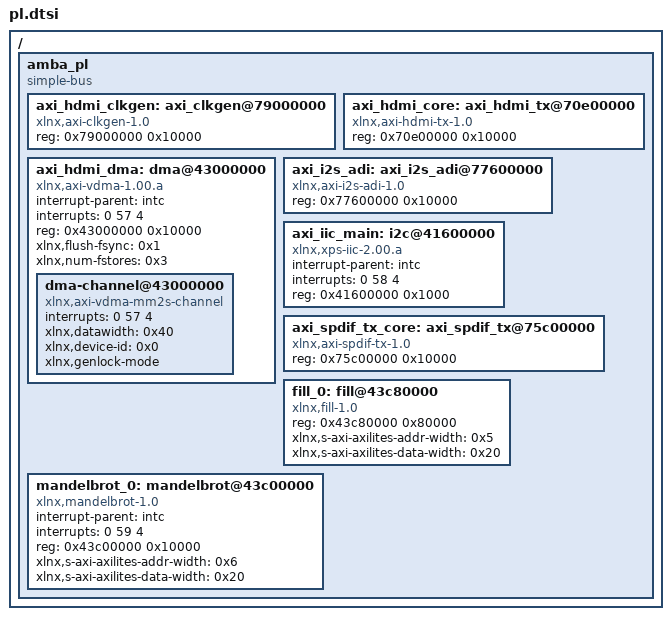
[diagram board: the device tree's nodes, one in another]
/*
 * CAUTION: This file is automatically generated by Xilinx.
 * Version:  
 * Today is: Tue Nov 29 21:41:55 2016
*/


/ {
	amba_pl: amba_pl {
		#address-cells = <1>;
		#size-cells = <1>;
		compatible = "simple-bus";
		ranges ;
		axi_hdmi_clkgen: axi_clkgen@79000000 {
			compatible = "xlnx,axi-clkgen-1.0";
			reg = <0x79000000 0x10000>;
		};
		axi_hdmi_core: axi_hdmi_tx@70e00000 {
			compatible = "xlnx,axi-hdmi-tx-1.0";
			reg = <0x70e00000 0x10000>;
		};
		axi_hdmi_dma: dma@43000000 {
			#dma-cells = <1>;
			compatible = "xlnx,axi-vdma-1.00.a";
			interrupt-parent = <&intc>;
			interrupts = <0 57 4>;
			reg = <0x43000000 0x10000>;
			xlnx,flush-fsync = <0x1>;
			xlnx,num-fstores = <0x3>;
			dma-channel@43000000 {
				compatible = "xlnx,axi-vdma-mm2s-channel";
				interrupts = <0 57 4>;
				xlnx,datawidth = <0x40>;
				xlnx,device-id = <0x0>;
				xlnx,genlock-mode ;
			};
		};
		axi_i2s_adi: axi_i2s_adi@77600000 {
			compatible = "xlnx,axi-i2s-adi-1.0";
			reg = <0x77600000 0x10000>;
		};
		axi_iic_main: i2c@41600000 {
			#address-cells = <1>;
			#size-cells = <0>;
			compatible = "xlnx,xps-iic-2.00.a";
			interrupt-parent = <&intc>;
			interrupts = <0 58 4>;
			reg = <0x41600000 0x1000>;
		};
		axi_spdif_tx_core: axi_spdif_tx@75c00000 {
			compatible = "xlnx,axi-spdif-tx-1.0";
			reg = <0x75c00000 0x10000>;
		};
		fill_0: fill@43c80000 {
			compatible = "xlnx,fill-1.0";
			reg = <0x43c80000 0x80000>;
			xlnx,s-axi-axilites-addr-width = <0x5>;
			xlnx,s-axi-axilites-data-width = <0x20>;
		};
		mandelbrot_0: mandelbrot@43c00000 {
			compatible = "xlnx,mandelbrot-1.0";
			interrupt-parent = <&intc>;
			interrupts = <0 59 4>;
			reg = <0x43c00000 0x10000>;
			xlnx,s-axi-axilites-addr-width = <0x6>;
			xlnx,s-axi-axilites-data-width = <0x20>;
		};
	};
};
